// Description: LIN Description file created using Vector's Network Designer

// Created: 12 Mar 2013 16:30:13

// Author: u074570

LIN_description_file;
LIN_protocol_version = "2.0";
LIN_language_version = "2.0";
LIN_speed = 9.6 kbps;

Nodes {
  Master: BSG_Master, 5 ms, 0 ms ;
  Slaves: Tester ;
}

Signals {
  Button_KL15: 1, 0, BSG_Master, Tester ;
  Voltage_Normal: 1, 0, BSG_Master, Tester ;
  Voltage_OV1: 1, 0, BSG_Master, Tester ;
  Voltage_OV2: 1, 0, BSG_Master, Tester ;
  Voltage_UV1: 1, 0, BSG_Master, Tester ;
  Voltage_UV2: 1, 0, BSG_Master, Tester ;
  BatteryVoltage: 16, 0, BSG_Master, Tester ;
  ResponseErrorTester: 1, 0, Tester, BSG_Master ;
}

Frames {
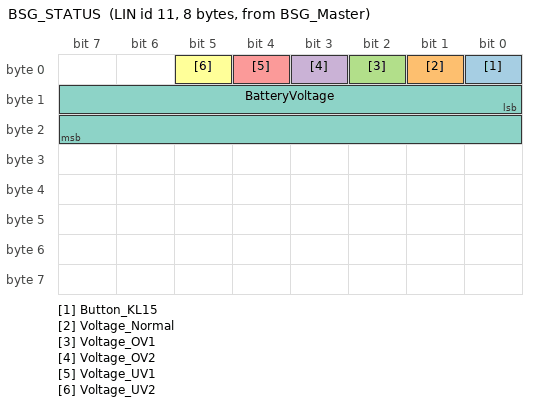
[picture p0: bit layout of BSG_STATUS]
  BSG_STATUS: 11, BSG_Master, 8 {
    Button_KL15, 0 ;
    Voltage_Normal, 1 ;
    Voltage_OV1, 2 ;
    Voltage_OV2, 3 ;
    Voltage_UV1, 4 ;
    Voltage_UV2, 5 ;
    BatteryVoltage, 8 ;
  }
  TESTER_STATUS: 12, Tester, 1 {
    ResponseErrorTester, 0 ;
  }
}

Node_attributes {
  Tester{
    LIN_protocol = "2.1" ;
    configured_NAD = 0x17 ;
    initial_NAD = 0x17 ;
    product_id = 0x0, 0x0, 0 ;
    response_error = ResponseErrorTester ;
    P2_min = 50 ms ;
    ST_min = 0 ms ;
    N_As_timeout = 1000 ms ;
    N_Cr_timeout = 1000 ms ;
    configurable_frames {
      BSG_STATUS ;
      TESTER_STATUS ;
    }
  }
}

Schedule_tables {
 DEFAULTTABLE {
    BSG_STATUS delay 100 ms ;
    TESTER_STATUS delay 100 ms ;
  }
}

Signal_encoding_types {
  ButtonSts_Encoding {
    logical_value, 0, "Button released" ;
    logical_value, 1, "Button pressed" ;
  }
  ResponseError_Sig_Type {
    logical_value, 0, "Node_Is_Operating_Correctly" ;
    logical_value, 1, "Node_Has_Intermittent_Problems" ;
  }
}

Signal_representation {
  ButtonSts_Encoding: Button_KL15 ;
}
